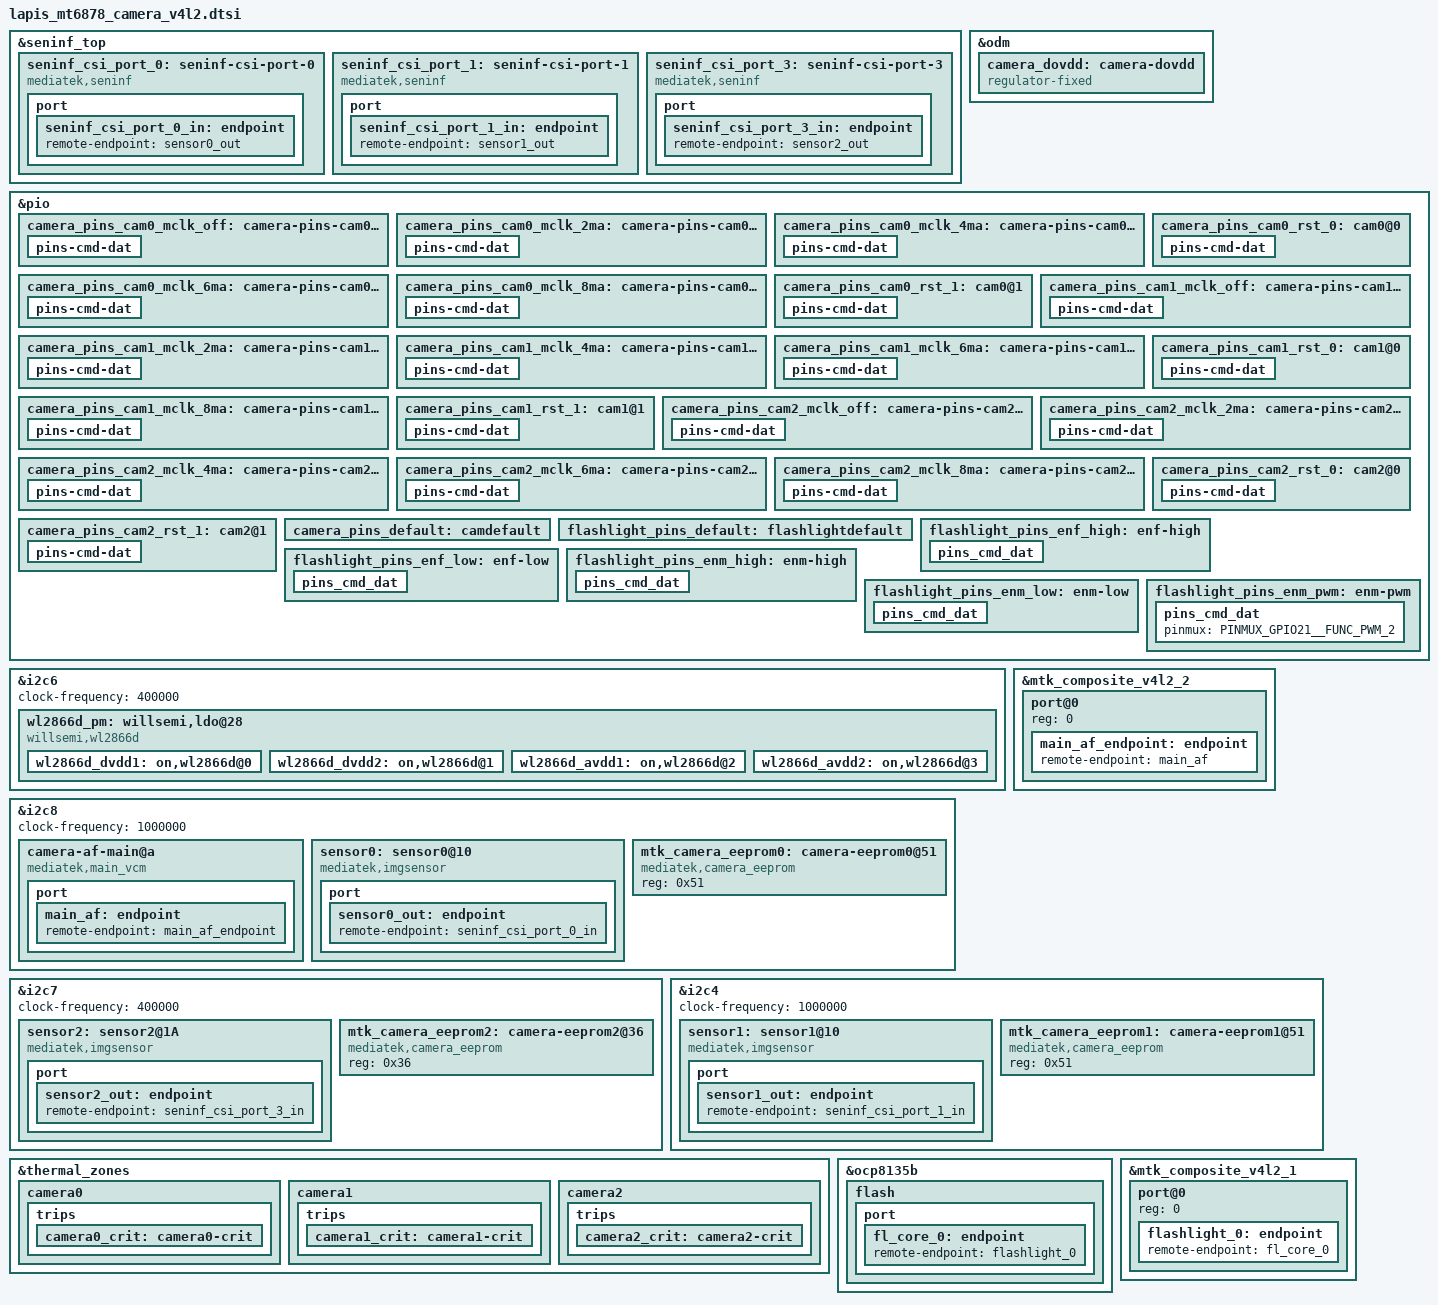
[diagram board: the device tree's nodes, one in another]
// SPDX-License-Identifier: GPL-2.0
/* Copyright (c) 2020 MediaTek Inc. */
#include <dt-bindings/clock/mt6878-clk.h>

&seninf_top {
		seninf_csi_port_0: seninf-csi-port-0 {
			compatible = "mediatek,seninf";
			csi-port = "0";
			nvmem-cells = <&csi_efuse0>;
			nvmem-cell-names = "rg_csi";
			port {
				seninf_csi_port_0_in: endpoint {
					remote-endpoint = <&sensor0_out>;
				};
			};
		};

		seninf_csi_port_1: seninf-csi-port-1 {

			compatible = "mediatek,seninf";
			csi-port = "1";
			nvmem-cells = <&csi_efuse1>;
			nvmem-cell-names = "rg_csi";
			port {
				seninf_csi_port_1_in: endpoint {
					remote-endpoint = <&sensor1_out>;
				};
			};
		};

		seninf_csi_port_3: seninf-csi-port-3 {
			compatible = "mediatek,seninf";
			csi-port = "3";
			nvmem-cells = <&csi_efuse3>;
			nvmem-cell-names = "rg_csi";
			port {
				seninf_csi_port_3_in: endpoint {
					remote-endpoint = <&sensor2_out>;
				};
			};
		};
};

/* CAMERA GPIO fixed to regulator */
&odm {
	camera_dovdd: camera-dovdd {
		compatible = "regulator-fixed";
		regulator-name = "camera-dovdd";
		regulator-min-microvolt = <1800000>;
		regulator-max-microvolt = <1800000>;
		enable-active-high;
		gpio = <&pio 23 0x0>;
	};
};

/* CAMERA GPIO standardization */
&pio {
	camera_pins_cam0_mclk_off: camera-pins-cam0-mclk-off {
		pins-cmd-dat {
			pinmux = <PINMUX_GPIO96__FUNC_GPIO96>;
			drive-strength = <1>;
		};
	};
	camera_pins_cam0_mclk_2ma: camera-pins-cam0-mclk-2ma {
		pins-cmd-dat {
			pinmux = <PINMUX_GPIO96__FUNC_CMMCLK4>;
			drive-strength = <0>;
		};
	};
	camera_pins_cam0_mclk_4ma: camera-pins-cam0-mclk-4ma {
		pins-cmd-dat {
			pinmux = <PINMUX_GPIO96__FUNC_CMMCLK4>;
			drive-strength = <1>;
		};
	};
	camera_pins_cam0_mclk_6ma: camera-pins-cam0-mclk-6ma {
		pins-cmd-dat {
			pinmux = <PINMUX_GPIO96__FUNC_CMMCLK4>;
			drive-strength = <2>;
		};
	};
	camera_pins_cam0_mclk_8ma: camera-pins-cam0-mclk-8ma {
		pins-cmd-dat {
			pinmux = <PINMUX_GPIO96__FUNC_CMMCLK4>;
			drive-strength = <3>;
		};
	};
	camera_pins_cam0_rst_0: cam0@0 {
		pins-cmd-dat {
			pinmux = <PINMUX_GPIO24__FUNC_GPIO24>;
			slew-rate = <1>;
			output-low;
		};
	};
	camera_pins_cam0_rst_1: cam0@1 {
		pins-cmd-dat {
			pinmux = <PINMUX_GPIO24__FUNC_GPIO24>;
			slew-rate = <1>;
			output-high;
		};
	};

	camera_pins_cam1_mclk_off: camera-pins-cam1-mclk-off {
		pins-cmd-dat {
			pinmux = <PINMUX_GPIO93__FUNC_GPIO93>;
			drive-strength = <1>;
		};
	};
	camera_pins_cam1_mclk_2ma: camera-pins-cam1-mclk-2ma {
		pins-cmd-dat {
			pinmux = <PINMUX_GPIO93__FUNC_CMMCLK1>;
			drive-strength = <0>;
		};
	};
	camera_pins_cam1_mclk_4ma: camera-pins-cam1-mclk-4ma {
		pins-cmd-dat {
			pinmux = <PINMUX_GPIO93__FUNC_CMMCLK1>;
			drive-strength = <1>;
		};
	};
	camera_pins_cam1_mclk_6ma: camera-pins-cam1-mclk-6ma {
		pins-cmd-dat {
			pinmux = <PINMUX_GPIO93__FUNC_CMMCLK1>;
			drive-strength = <2>;
		};
	};
	camera_pins_cam1_mclk_8ma: camera-pins-cam1-mclk-8ma {
		pins-cmd-dat {
			pinmux = <PINMUX_GPIO93__FUNC_CMMCLK1>;
			drive-strength = <3>;
		};
	};
	camera_pins_cam1_rst_0: cam1@0 {
		pins-cmd-dat {
			pinmux = <PINMUX_GPIO25__FUNC_GPIO25>;
			slew-rate = <1>;
			output-low;
		};
	};
	camera_pins_cam1_rst_1: cam1@1 {
		pins-cmd-dat {
			pinmux = <PINMUX_GPIO25__FUNC_GPIO25>;
			slew-rate = <1>;
			output-high;
		};
	};

	camera_pins_cam2_mclk_off: camera-pins-cam2-mclk-off {
		pins-cmd-dat {
			pinmux = <PINMUX_GPIO95__FUNC_GPIO95>;
			drive-strength = <1>;
		};
	};
	camera_pins_cam2_mclk_2ma: camera-pins-cam2-mclk-2ma {
		pins-cmd-dat {
			pinmux = <PINMUX_GPIO95__FUNC_CMMCLK3>;
			drive-strength = <0>;
		};
	};
	camera_pins_cam2_mclk_4ma: camera-pins-cam2-mclk-4ma {
		pins-cmd-dat {
			pinmux = <PINMUX_GPIO95__FUNC_CMMCLK3>;
			drive-strength = <1>;
		};
	};
	camera_pins_cam2_mclk_6ma: camera-pins-cam2-mclk-6ma {
		pins-cmd-dat {
			pinmux = <PINMUX_GPIO95__FUNC_CMMCLK3>;
			drive-strength = <2>;
		};
	};
	camera_pins_cam2_mclk_8ma: camera-pins-cam2-mclk-8ma {
		pins-cmd-dat {
			pinmux = <PINMUX_GPIO95__FUNC_CMMCLK3>;
			drive-strength = <3>;
		};
	};
	camera_pins_cam2_rst_0: cam2@0 {
		pins-cmd-dat {
			pinmux = <PINMUX_GPIO27__FUNC_GPIO27>;
			slew-rate = <1>;
			output-low;
		};
	};
	camera_pins_cam2_rst_1: cam2@1 {
		pins-cmd-dat {
			pinmux = <PINMUX_GPIO27__FUNC_GPIO27>;
			slew-rate = <1>;
			output-high;
		};
	};

	camera_pins_default: camdefault {
	};
};

&i2c6 {
	status = "okay";
	clock-frequency = <400000>;

	wl2866d_pm:willsemi,ldo@28 {
		compatible = "willsemi,wl2866d";
		reg = <0x28>;/*slave address*/
        index = <0>;

		wl2866d_dvdd1:on,wl2866d@0{
			offset = /bits/ 16 <0x0000>;
			regulator-name ="dvdd1";
			regulator-min-microvolt = <600000>;
			regulator-max-microvolt = <1800000>;
			min-dropout-voltage = <80000>;
			iout_ua = <500000>;
			init-voltage = <1100000>;
		};

		wl2866d_dvdd2:on,wl2866d@1{
			offset = /bits/ 16 <0x0001>;
			regulator-name ="dvdd2";
			regulator-min-microvolt = <600000>;
			regulator-max-microvolt = <1800000>;
			min-dropout-voltage = <80000>;
			iout_ua = <500000>;
			init-voltage = <1200000>;
		};

		wl2866d_avdd1:on,wl2866d@2{
			offset = /bits/ 16 <0x0002>;
			regulator-name ="avdd1";
			regulator-min-microvolt = <1200000>;
			regulator-max-microvolt = <4300000>;
			min-dropout-voltage = <90000>;
			iout_ua = <300000>;
			init-voltage = <3100000>;
		};

		wl2866d_avdd2:on,wl2866d@3{
			offset = /bits/ 16 <0x0003>;
			regulator-name ="avdd2";
			regulator-min-microvolt = <1200000>;
			regulator-max-microvolt = <4300000>;
			min-dropout-voltage = <90000>;
			iout_ua = <300000>;
			init-voltage = <2800000>;
		};
	};
};

/* CAMERA GPIO end */
&i2c8 {
	status = "okay";
	clock-frequency = <1000000>;

	camera-af-main@a {
		compatible = "mediatek,main_vcm";
		reg = <0x0a>;
		vin-supply = <&mt6369_vibr>;
		port {
			main_af: endpoint {
				remote-endpoint = <&main_af_endpoint>;
			};
		};
	};
	sensor0: sensor0@10 {
		compatible = "mediatek,imgsensor";
		sensor-names = "lapisimx882wide_mipi_raw","lapiss5khpewide_mipi_raw";
		reg = <0x10>;
		#thermal-sensor-cells = <0>;

		pinctrl-names = "mclk_off",
				"mclk_2mA",
				"mclk_4mA",
				"mclk_6mA",
				"mclk_8mA",
				"rst_low",
				"rst_high";
		pinctrl-0 = <&camera_pins_cam0_mclk_off>;
		pinctrl-1 = <&camera_pins_cam0_mclk_2ma>;
		pinctrl-2 = <&camera_pins_cam0_mclk_4ma>;
		pinctrl-3 = <&camera_pins_cam0_mclk_6ma>;
		pinctrl-4 = <&camera_pins_cam0_mclk_8ma>;
		pinctrl-5 = <&camera_pins_cam0_rst_0>;
		pinctrl-6 = <&camera_pins_cam0_rst_1>;

		avdd-supply = <&wl2866d_avdd1>;
		dvdd-supply = <&wl2866d_dvdd1>;
		afvdd-supply = <&mt6369_vibr>;
		dovdd-supply = <&camera_dovdd>;

		clocks = <&topckgen_clk CLK_TOP_UVPLL192M_D32>,
			<&topckgen_clk CLK_TOP_UVPLL192M_D16>,
			<&topckgen_clk CLK_TOP_OSC_D20>,
			<&topckgen_clk CLK_TOP_UVPLL192M_D10>,
			<&topckgen_clk CLK_TOP_UVPLL192M_D8>,
			<&topckgen_clk CLK_TOP_TCK_26M_MX9>,
			<&topckgen_clk CLK_TOP_UNIVPLL_D6_D8>,
			<&topckgen_clk CLK_TOP_CAMTG5_SEL>;
		clock-names = "6", "12", "13", "19.2", "24", "26", "52", "mclk";

		status = "okay";
		port {
			sensor0_out: endpoint {
				remote-endpoint = <&seninf_csi_port_0_in>;
			};
		};
	};
	mtk_camera_eeprom0:camera-eeprom0@51 {
		compatible = "mediatek,camera_eeprom";
		reg = <0x51>;
		status = "okay";
	};
};
&mtk_composite_v4l2_2 {
	#address-cells = <1>;
	#size-cells = <0>;
	port@0 {
		reg = <0>;
		main_af_endpoint: endpoint {
			remote-endpoint = <&main_af>;
		};
	};
};
&i2c7 {
	status = "okay";
	clock-frequency = <400000>;

	sensor2: sensor2@1A {
		compatible = "mediatek,imgsensor";
		sensor-names = "lapisov08f10ultra_mipi_raw";
		reg = <0x10>;

		#thermal-sensor-cells = <0>;

		pinctrl-names = "mclk_off",
				"mclk_2mA",
				"mclk_4mA",
				"mclk_6mA",
				"mclk_8mA",
				"rst_low",
				"rst_high";
		pinctrl-0 = <&camera_pins_cam2_mclk_off>;
		pinctrl-1 = <&camera_pins_cam2_mclk_2ma>;
		pinctrl-2 = <&camera_pins_cam2_mclk_4ma>;
		pinctrl-3 = <&camera_pins_cam2_mclk_6ma>;
		pinctrl-4 = <&camera_pins_cam2_mclk_8ma>;
		pinctrl-5 = <&camera_pins_cam2_rst_0>;
		pinctrl-6 = <&camera_pins_cam2_rst_1>;

		avdd-supply = <&wl2866d_avdd2>;
		dvdd-supply = <&wl2866d_dvdd2>;
		dovdd-supply = <&camera_dovdd>;

		clocks = <&topckgen_clk CLK_TOP_UVPLL192M_D32>,
			<&topckgen_clk CLK_TOP_UVPLL192M_D16>,
			<&topckgen_clk CLK_TOP_OSC_D20>,
			<&topckgen_clk CLK_TOP_UVPLL192M_D10>,
			<&topckgen_clk CLK_TOP_UVPLL192M_D8>,
			<&topckgen_clk CLK_TOP_TCK_26M_MX9>,
			<&topckgen_clk CLK_TOP_UNIVPLL_D6_D8>,
			<&topckgen_clk CLK_TOP_CAMTG4_SEL>;
		clock-names = "6", "12", "13", "19.2", "24", "26", "52", "mclk";

		status = "okay";
		port {
			sensor2_out: endpoint {
				remote-endpoint = <&seninf_csi_port_3_in>;
			};
		};
	};
	mtk_camera_eeprom2:camera-eeprom2@36 {
		compatible = "mediatek,camera_eeprom";
		reg = <0x36>;
		status = "okay";
	};
};

&i2c4 {
	status = "okay";
	clock-frequency = <1000000>;

	sensor1: sensor1@10 {
		compatible = "mediatek,imgsensor";
		sensor-names = "lapisov20bfront_mipi_raw";
		reg = <0x10>;

		pinctrl-names = "mclk_off",
				"mclk_2mA",
				"mclk_4mA",
				"mclk_6mA",
				"mclk_8mA",
				"rst_low",
				"rst_high";
		pinctrl-0 = <&camera_pins_cam1_mclk_off>;
		pinctrl-1 = <&camera_pins_cam1_mclk_2ma>;
		pinctrl-2 = <&camera_pins_cam1_mclk_4ma>;
		pinctrl-3 = <&camera_pins_cam1_mclk_6ma>;
		pinctrl-4 = <&camera_pins_cam1_mclk_8ma>;
		pinctrl-5 = <&camera_pins_cam1_rst_0>;
		pinctrl-6 = <&camera_pins_cam1_rst_1>;

		avdd-supply = <&wl2866d_avdd2>;
		dvdd-supply = <&wl2866d_dvdd2>;
		dovdd-supply = <&camera_dovdd>;

		clocks = <&topckgen_clk CLK_TOP_UVPLL192M_D32>,
			<&topckgen_clk CLK_TOP_UVPLL192M_D16>,
			<&topckgen_clk CLK_TOP_OSC_D20>,
			<&topckgen_clk CLK_TOP_UVPLL192M_D10>,
			<&topckgen_clk CLK_TOP_UVPLL192M_D8>,
			<&topckgen_clk CLK_TOP_TCK_26M_MX9>,
			<&topckgen_clk CLK_TOP_UNIVPLL_D6_D8>,
			<&topckgen_clk CLK_TOP_CAMTG2_SEL>;
		clock-names = "6", "12", "13", "19.2", "24", "26", "52", "mclk";

		status = "okay";
		port {
			sensor1_out: endpoint {
				remote-endpoint = <&seninf_csi_port_1_in>;
			};
		};
	};
	mtk_camera_eeprom1:camera-eeprom1@51 {
		compatible = "mediatek,camera_eeprom";
		reg = <0x51>;
		status = "okay";
	};
};

&thermal_zones {
	camera0: camera0 {
		polling-delay = <0>; /* milliseconds */
		polling-delay-passive = <0>; /* milliseconds */
		thermal-sensors = <&sensor0>;
		trips {
			camera0_crit: camera0-crit {
				temperature = <120000>;
				hysteresis = <2000>;
				type = "passive";
			};
		};
	};
	camera1: camera1 {
		polling-delay = <0>; /* milliseconds */
		polling-delay-passive = <0>; /* milliseconds */
		thermal-sensors = <&sensor1>;
		trips {
			camera1_crit: camera1-crit {
				temperature = <120000>;
				hysteresis = <2000>;
				type = "passive";
			};
		};
	};
	camera2: camera2 {
		polling-delay = <0>; /* milliseconds */
		polling-delay-passive = <0>; /* milliseconds */
		thermal-sensors = <&sensor2>;
		trips {
			camera2_crit: camera2-crit {
				temperature = <120000>;
				hysteresis = <2000>;
				type = "passive";
			};
		};
	};
};

&ocp8135b {

        pinctrl-names = "default", "enf-high",
                "enf-low", "enm-high", "enm-low","enm-pwm";
        pinctrl-0 = <&flashlight_pins_default>;
        pinctrl-1 = <&flashlight_pins_enf_high>;
        pinctrl-2 = <&flashlight_pins_enf_low>;
        pinctrl-3 = <&flashlight_pins_enm_high>;
        pinctrl-4 = <&flashlight_pins_enm_low>;
        pinctrl-5 = <&flashlight_pins_enm_pwm>;
        status = "okay";
		flash {
			reg = <0>;
			type = <0>;
			ct = <0>;
			part = <0>;
			port {
				fl_core_0: endpoint {
					remote-endpoint = <&flashlight_0>;
				};
			};
		};
};
&pio {
        flashlight_pins_default: flashlightdefault {
        };
        flashlight_pins_enf_high: enf-high {
                pins_cmd_dat {
                        pinmux = <PINMUX_GPIO155__FUNC_GPIO155>;
                        slew-rate = <1>;
                        output-high;
                };
        };
        flashlight_pins_enf_low: enf-low {
                pins_cmd_dat {
                        pinmux = <PINMUX_GPIO155__FUNC_GPIO155>;
                        slew-rate = <1>;
                        output-low;
                };
        };
        flashlight_pins_enm_high: enm-high {
                pins_cmd_dat {
                        pinmux = <PINMUX_GPIO21__FUNC_GPIO21>;
                        slew-rate = <1>;
                        output-high;
                };
        };
        flashlight_pins_enm_low: enm-low {
                pins_cmd_dat {
                        pinmux = <PINMUX_GPIO21__FUNC_GPIO21>;
                        slew-rate = <1>;
                        output-low;
                };
        };
        flashlight_pins_enm_pwm: enm-pwm {
                pins_cmd_dat {
                        pinmux = <PINMUX_GPIO21__FUNC_PWM_2>;
                };
        };
};

&mtk_composite_v4l2_1 {
	#address-cells = <1>;
	#size-cells = <0>;
	port@0 {
		reg = <0>;
		flashlight_0: endpoint {
			remote-endpoint = <&fl_core_0>;
		};
	};
};
